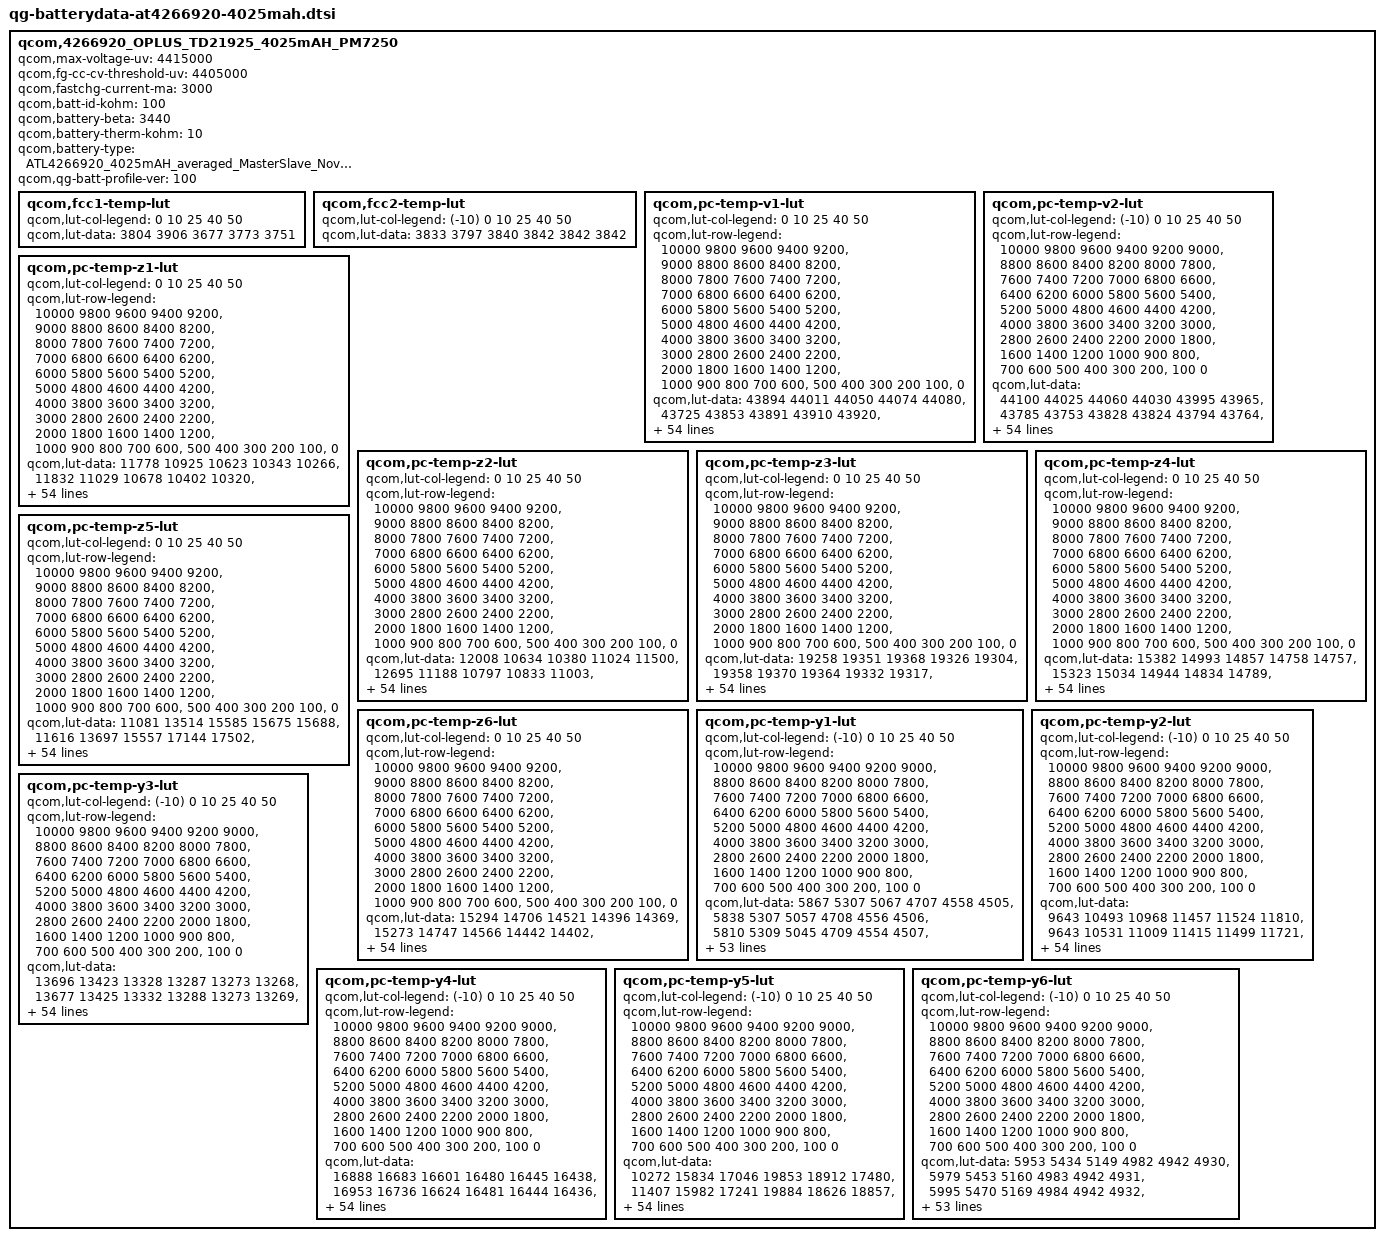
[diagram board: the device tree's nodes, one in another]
qcom,4266920_OPLUS_TD21925_4025mAH_PM7250 {
    /* 4266920_OPLUS_TD21925_4025mAH_PM7250_averaged_MasterSlave_Nov29th2019 */
    qcom,max-voltage-uv = <4415000>;
    qcom,fg-cc-cv-threshold-uv = <4405000>;
    qcom,fastchg-current-ma = <3000>;
    qcom,batt-id-kohm = <100>;
    qcom,battery-beta = <3440>;
    qcom,battery-therm-kohm = <10>;
    qcom,battery-type = "ATL4266920_4025mAH_averaged_MasterSlave_Nov29th2019";
    qcom,qg-batt-profile-ver = <100>;


	qcom,fcc1-temp-lut {
		qcom,lut-col-legend = <0 10 25 40 50>;
		qcom,lut-data = <3804 3906 3677 3773 3751>;
	};

	qcom,fcc2-temp-lut {
		qcom,lut-col-legend = <(-10) 0 10 25 40 50>;
		qcom,lut-data = <3833 3797 3840 3842 3842 3842>;
	};

	qcom,pc-temp-v1-lut {
		qcom,lut-col-legend = <0 10 25 40 50>;
		qcom,lut-row-legend = <10000 9800 9600 9400 9200>,
			<9000 8800 8600 8400 8200>,
			<8000 7800 7600 7400 7200>,
			<7000 6800 6600 6400 6200>,
			<6000 5800 5600 5400 5200>,
			<5000 4800 4600 4400 4200>,
			<4000 3800 3600 3400 3200>,
			<3000 2800 2600 2400 2200>,
			<2000 1800 1600 1400 1200>,
			<1000 900 800 700 600>,
			<500 400 300 200 100>,
			<0>;
		qcom,lut-data = <43894 44011 44050 44074 44080>,
			<43725 43853 43891 43910 43920>,
			<43525 43681 43703 43730 43743>,
			<43298 43490 43505 43539 43554>,
			<43066 43276 43296 43337 43354>,
			<42830 43046 43076 43121 43140>,
			<42595 42811 42850 42899 42917>,
			<42367 42574 42617 42672 42690>,
			<42143 42341 42384 42440 42457>,
			<41922 42111 42152 42208 42224>,
			<41705 41883 41921 41975 41991>,
			<41492 41660 41694 41745 41759>,
			<41283 41441 41472 41520 41535>,
			<41082 41229 41255 41299 41315>,
			<40886 41025 41045 41085 41100>,
			<40689 40827 40841 40879 40890>,
			<40488 40635 40644 40680 40686>,
			<40290 40448 40461 40492 40493>,
			<40104 40249 40281 40313 40314>,
			<39931 39996 40064 40115 40122>,
			<39748 39701 39784 39859 39880>,
			<39513 39457 39520 39593 39616>,
			<39249 39296 39341 39388 39402>,
			<39059 39170 39197 39223 39234>,
			<38950 39052 39066 39078 39087>,
			<38866 38940 38940 38946 38952>,
			<38783 38835 38823 38827 38830>,
			<38704 38733 38715 38717 38716>,
			<38629 38637 38614 38616 38609>,
			<38557 38550 38521 38521 38509>,
			<38489 38476 38437 38433 38417>,
			<38426 38407 38361 38350 38332>,
			<38371 38347 38292 38273 38253>,
			<38320 38291 38231 38203 38181>,
			<38274 38240 38174 38136 38111>,
			<38236 38197 38118 38064 38032>,
			<38195 38157 38065 37990 37943>,
			<38132 38102 38001 37909 37849>,
			<38036 38011 37912 37819 37751>,
			<37924 37894 37802 37718 37646>,
			<37803 37769 37683 37604 37528>,
			<37664 37628 37549 37469 37392>,
			<37503 37469 37399 37325 37246>,
			<37345 37296 37230 37167 37087>,
			<37248 37178 37115 37058 36992>,
			<37170 37119 37058 37006 36946>,
			<37145 37093 37040 36989 36931>,
			<37121 37071 37022 36973 36915>,
			<37069 37028 36974 36931 36854>,
			<36894 36849 36792 36732 36587>,
			<36507 36451 36400 36344 36189>,
			<36007 35950 35911 35860 35692>,
			<35368 35309 35285 35235 35052>,
			<34487 34417 34431 34384 34171>,
			<33063 32979 33080 33048 32769>,
			<30000 30000 30000 30000 30000>;
	};

	qcom,pc-temp-v2-lut {
		qcom,lut-col-legend = <(-10) 0 10 25 40 50>;
		qcom,lut-row-legend = <10000 9800 9600 9400 9200 9000>,
			<8800 8600 8400 8200 8000 7800>,
			<7600 7400 7200 7000 6800 6600>,
			<6400 6200 6000 5800 5600 5400>,
			<5200 5000 4800 4600 4400 4200>,
			<4000 3800 3600 3400 3200 3000>,
			<2800 2600 2400 2200 2000 1800>,
			<1600 1400 1200 1000 900 800>,
			<700 600 500 400 300 200>,
			<100 0>;
		qcom,lut-data = <44100 44025 44060 44030 43995 43965>,
			<43785 43753 43828 43824 43794 43764>,
			<43492 43491 43599 43615 43589 43559>,
			<43225 43241 43373 43404 43380 43351>,
			<42986 43007 43152 43189 43168 43138>,
			<42753 42776 42929 42970 42951 42921>,
			<42504 42537 42697 42743 42725 42696>,
			<42247 42293 42459 42509 42494 42465>,
			<41988 42056 42223 42276 42263 42235>,
			<41705 41833 41986 42044 42033 42004>,
			<41437 41615 41753 41813 41804 41776>,
			<41262 41387 41526 41586 41580 41551>,
			<41150 41143 41305 41363 41358 41330>,
			<41024 40915 41090 41146 41142 41114>,
			<40804 40739 40883 40935 40930 40905>,
			<40485 40592 40683 40730 40724 40702>,
			<40174 40412 40479 40531 40525 40505>,
			<39879 40145 40272 40344 40341 40323>,
			<39597 39840 40056 40150 40150 40134>,
			<39345 39573 39811 39913 39918 39903>,
			<39106 39328 39541 39637 39646 39631>,
			<38895 39105 39302 39390 39405 39392>,
			<38706 38910 39108 39195 39216 39207>,
			<38542 38735 38939 39025 39053 39047>,
			<38424 38569 38787 38877 38910 38906>,
			<38338 38394 38653 38749 38783 38779>,
			<38267 38240 38530 38631 38666 38663>,
			<38203 38149 38414 38521 38557 38556>,
			<38147 38089 38305 38418 38455 38456>,
			<38092 38041 38199 38322 38360 38361>,
			<38039 37996 38092 38232 38274 38274>,
			<37988 37956 37993 38147 38192 38190>,
			<37934 37915 37923 38070 38112 38107>,
			<37877 37871 37870 37999 38033 38023>,
			<37818 37825 37823 37924 37945 37928>,
			<37753 37774 37780 37836 37837 37809>,
			<37683 37716 37736 37740 37718 37677>,
			<37606 37650 37679 37645 37610 37561>,
			<37520 37565 37600 37554 37514 37464>,
			<37423 37461 37504 37459 37416 37366>,
			<37311 37343 37388 37352 37304 37252>,
			<37181 37198 37245 37232 37177 37122>,
			<37062 37050 37100 37109 37055 36998>,
			<36965 36923 36950 36978 36935 36884>,
			<36884 36816 36835 36891 36860 36813>,
			<36814 36747 36777 36860 36833 36788>,
			<36774 36725 36748 36842 36819 36773>,
			<36716 36693 36706 36810 36788 36735>,
			<36608 36615 36609 36723 36687 36603>,
			<36400 36429 36390 36522 36444 36303>,
			<36033 36062 35963 36095 35999 35849>,
			<35500 35519 35401 35563 35465 35295>,
			<34766 34822 34683 34889 34766 34567>,
			<33702 33829 33674 33961 33824 33553>,
			<31807 32174 32032 32452 32402 31793>,
			<27093 27571 27094 29575 28936 27567>;
	};

	qcom,pc-temp-z1-lut {
		qcom,lut-col-legend = <0 10 25 40 50>;
		qcom,lut-row-legend = <10000 9800 9600 9400 9200>,
			<9000 8800 8600 8400 8200>,
			<8000 7800 7600 7400 7200>,
			<7000 6800 6600 6400 6200>,
			<6000 5800 5600 5400 5200>,
			<5000 4800 4600 4400 4200>,
			<4000 3800 3600 3400 3200>,
			<3000 2800 2600 2400 2200>,
			<2000 1800 1600 1400 1200>,
			<1000 900 800 700 600>,
			<500 400 300 200 100>,
			<0>;
		qcom,lut-data = <11778 10925 10623 10343 10266>,
			<11832 11029 10678 10402 10320>,
			<11841 11179 10689 10412 10334>,
			<11839 11265 10691 10415 10339>,
			<11841 11255 10686 10414 10341>,
			<11845 11239 10679 10413 10342>,
			<11843 11224 10673 10412 10342>,
			<11829 11208 10667 10411 10342>,
			<11799 11191 10663 10410 10341>,
			<11769 11172 10660 10409 10341>,
			<11755 11162 10658 10408 10341>,
			<11752 11163 10657 10407 10340>,
			<11754 11173 10659 10408 10340>,
			<11751 11182 10660 10408 10341>,
			<11749 11177 10661 10408 10342>,
			<11747 11167 10663 10408 10343>,
			<11744 11165 10663 10409 10343>,
			<11740 11171 10663 10409 10344>,
			<11735 11176 10663 10410 10345>,
			<11726 11171 10663 10411 10345>,
			<11722 11163 10664 10411 10346>,
			<11727 11162 10666 10411 10347>,
			<11730 11169 10667 10412 10348>,
			<11733 11178 10669 10414 10349>,
			<11743 11180 10671 10417 10351>,
			<11756 11179 10678 10419 10353>,
			<11762 11177 10687 10421 10355>,
			<11761 11175 10692 10423 10357>,
			<11759 11176 10694 10426 10359>,
			<11763 11179 10696 10428 10361>,
			<11770 11192 10697 10430 10363>,
			<11772 11206 10699 10433 10365>,
			<11760 11207 10701 10436 10368>,
			<11744 11199 10709 10439 10371>,
			<11740 11195 10718 10442 10373>,
			<11747 11199 10724 10445 10376>,
			<11756 11207 10731 10448 10378>,
			<11764 11216 10734 10451 10380>,
			<11777 11236 10737 10454 10382>,
			<11793 11259 10739 10456 10383>,
			<11821 11264 10742 10458 10384>,
			<11852 11264 10749 10460 10386>,
			<11846 11258 10753 10461 10387>,
			<11833 11246 10756 10461 10388>,
			<11870 11253 10766 10462 10389>,
			<11826 11250 10766 10465 10389>,
			<11825 11246 10764 10466 10390>,
			<11805 11251 10772 10466 10390>,
			<11814 11270 10779 10468 10392>,
			<11817 11289 10788 10472 10394>,
			<11835 11274 10794 10474 10397>,
			<11874 11291 10797 10480 10400>,
			<11870 11295 10803 10484 10404>,
			<11879 11315 10816 10492 10411>,
			<11879 11315 10816 10492 10411>,
			<11879 11315 10816 10492 10411>;
	};

	qcom,pc-temp-z2-lut {
		qcom,lut-col-legend = <0 10 25 40 50>;
		qcom,lut-row-legend = <10000 9800 9600 9400 9200>,
			<9000 8800 8600 8400 8200>,
			<8000 7800 7600 7400 7200>,
			<7000 6800 6600 6400 6200>,
			<6000 5800 5600 5400 5200>,
			<5000 4800 4600 4400 4200>,
			<4000 3800 3600 3400 3200>,
			<3000 2800 2600 2400 2200>,
			<2000 1800 1600 1400 1200>,
			<1000 900 800 700 600>,
			<500 400 300 200 100>,
			<0>;
		qcom,lut-data = <12008 10634 10380 11024 11500>,
			<12695 11188 10797 10833 11003>,
			<12009 11320 10764 10873 10873>,
			<11090 11152 10728 10901 10813>,
			<10556 10927 10673 10878 10793>,
			<10360 10728 10609 10813 10786>,
			<10245 10507 10587 10761 10782>,
			<10217 10371 10590 10713 10762>,
			<10202 10358 10598 10665 10735>,
			<10194 10366 10607 10650 10727>,
			<10193 10383 10617 10651 10738>,
			<10196 10396 10621 10656 10756>,
			<10203 10404 10619 10665 10775>,
			<10223 10411 10616 10680 10796>,
			<10251 10419 10618 10693 10809>,
			<10262 10427 10631 10710 10815>,
			<10264 10434 10642 10728 10820>,
			<10266 10441 10643 10744 10836>,
			<10270 10446 10643 10761 10875>,
			<10277 10443 10637 10779 10917>,
			<10282 10424 10611 10805 10958>,
			<10276 10406 10590 10833 10995>,
			<10264 10400 10626 10854 10997>,
			<10257 10402 10722 10882 10912>,
			<10261 10412 10766 10891 10797>,
			<10267 10431 10717 10839 10713>,
			<10273 10444 10644 10750 10635>,
			<10277 10440 10622 10692 10610>,
			<10281 10429 10615 10652 10632>,
			<10287 10423 10614 10628 10672>,
			<10294 10430 10626 10634 10714>,
			<10302 10444 10651 10661 10771>,
			<10310 10457 10673 10691 10829>,
			<10318 10470 10691 10723 10886>,
			<10325 10482 10707 10765 10940>,
			<10330 10489 10719 10831 10984>,
			<10335 10493 10728 10947 11031>,
			<10347 10501 10742 11027 11077>,
			<10370 10521 10784 11036 11132>,
			<10386 10541 10834 11036 11191>,
			<10382 10541 10841 11043 11197>,
			<10374 10530 10819 11075 11078>,
			<10386 10529 10812 11081 11009>,
			<10414 10548 10819 10970 11046>,
			<10283 10659 10857 10988 11085>,
			<10258 10670 10822 10970 11038>,
			<11590 10663 10805 10984 11052>,
			<10569 10695 10764 10976 11136>,
			<11295 10808 10781 11011 11182>,
			<11016 10748 10877 10902 10841>,
			<9937 10752 10852 10768 10776>,
			<9848 10743 10817 10744 10720>,
			<9707 10779 10733 10650 10658>,
			<9596 10547 10651 10578 10567>,
			<9596 10547 10651 10578 10567>,
			<9596 10547 10651 10578 10567>;
	};

	qcom,pc-temp-z3-lut {
		qcom,lut-col-legend = <0 10 25 40 50>;
		qcom,lut-row-legend = <10000 9800 9600 9400 9200>,
			<9000 8800 8600 8400 8200>,
			<8000 7800 7600 7400 7200>,
			<7000 6800 6600 6400 6200>,
			<6000 5800 5600 5400 5200>,
			<5000 4800 4600 4400 4200>,
			<4000 3800 3600 3400 3200>,
			<3000 2800 2600 2400 2200>,
			<2000 1800 1600 1400 1200>,
			<1000 900 800 700 600>,
			<500 400 300 200 100>,
			<0>;
		qcom,lut-data = <19258 19351 19368 19326 19304>,
			<19358 19370 19364 19332 19317>,
			<19451 19421 19390 19348 19327>,
			<19546 19478 19411 19364 19336>,
			<19612 19511 19420 19368 19341>,
			<19646 19525 19426 19371 19343>,
			<19667 19532 19426 19371 19344>,
			<19669 19534 19421 19364 19341>,
			<19668 19533 19414 19353 19338>,
			<19666 19528 19410 19349 19336>,
			<19663 19522 19406 19348 19335>,
			<19659 19517 19403 19347 19334>,
			<19654 19514 19399 19346 19331>,
			<19645 19511 19396 19344 19325>,
			<19636 19508 19394 19342 19322>,
			<19634 19505 19394 19338 19321>,
			<19637 19502 19393 19333 19320>,
			<19641 19499 19391 19330 19319>,
			<19641 19497 19389 19329 19316>,
			<19637 19504 19389 19327 19315>,
			<19634 19520 19390 19327 19316>,
			<19640 19529 19392 19328 19321>,
			<19653 19518 19392 19334 19327>,
			<19658 19500 19392 19359 19342>,
			<19654 19495 19394 19378 19354>,
			<19646 19505 19408 19379 19353>,
			<19642 19517 19424 19378 19350>,
			<19639 19522 19426 19376 19347>,
			<19637 19525 19423 19367 19344>,
			<19635 19526 19418 19357 19341>,
			<19634 19522 19412 19350 19336>,
			<19633 19516 19406 19345 19330>,
			<19631 19512 19401 19341 19325>,
			<19629 19511 19398 19338 19321>,
			<19626 19509 19396 19336 19317>,
			<19623 19507 19395 19337 19316>,
			<19618 19505 19395 19339 19317>,
			<19613 19502 19394 19341 19319>,
			<19607 19496 19392 19340 19323>,
			<19599 19490 19388 19338 19328>,
			<19594 19485 19385 19338 19329>,
			<19587 19483 19383 19340 19327>,
			<19579 19479 19380 19341 19326>,
			<19557 19471 19376 19335 19331>,
			<19314 19443 19364 19326 19319>,
			<19299 19423 19360 19320 19312>,
			<19272 19423 19357 19320 19309>,
			<19263 19413 19355 19316 19301>,
			<19262 19380 19352 19316 19302>,
			<19263 19395 19346 19333 19326>,
			<19266 19377 19344 19339 19328>,
			<19268 19364 19347 19341 19329>,
			<19273 19323 19353 19343 19330>,
			<19279 19336 19353 19345 19333>,
			<19279 19336 19353 19345 19333>,
			<19279 19336 19353 19345 19333>;
	};

	qcom,pc-temp-z4-lut {
		qcom,lut-col-legend = <0 10 25 40 50>;
		qcom,lut-row-legend = <10000 9800 9600 9400 9200>,
			<9000 8800 8600 8400 8200>,
			<8000 7800 7600 7400 7200>,
			<7000 6800 6600 6400 6200>,
			<6000 5800 5600 5400 5200>,
			<5000 4800 4600 4400 4200>,
			<4000 3800 3600 3400 3200>,
			<3000 2800 2600 2400 2200>,
			<2000 1800 1600 1400 1200>,
			<1000 900 800 700 600>,
			<500 400 300 200 100>,
			<0>;
		qcom,lut-data = <15382 14993 14857 14758 14757>,
			<15323 15034 14944 14834 14789>,
			<15256 15058 14916 14814 14780>,
			<15180 15043 14881 14782 14756>,
			<15106 14986 14843 14755 14733>,
			<15035 14920 14803 14728 14710>,
			<14971 14871 14774 14712 14694>,
			<14921 14834 14750 14707 14689>,
			<14882 14800 14734 14704 14685>,
			<14850 14772 14725 14699 14680>,
			<14822 14753 14718 14692 14674>,
			<14797 14743 14712 14684 14667>,
			<14779 14738 14707 14676 14663>,
			<14767 14735 14702 14669 14660>,
			<14759 14732 14697 14664 14656>,
			<14757 14730 14690 14660 14650>,
			<14759 14729 14687 14658 14644>,
			<14762 14732 14687 14656 14641>,
			<14763 14738 14687 14654 14639>,
			<14762 14769 14697 14655 14638>,
			<14761 14833 14767 14703 14668>,
			<14792 14873 14833 14770 14724>,
			<14860 14878 14835 14778 14739>,
			<14893 14878 14826 14749 14720>,
			<14881 14870 14812 14720 14698>,
			<14861 14840 14782 14705 14689>,
			<14842 14805 14748 14694 14682>,
			<14822 14784 14732 14687 14675>,
			<14805 14770 14722 14683 14669>,
			<14793 14764 14717 14680 14663>,
			<14783 14763 14715 14676 14659>,
			<14776 14762 14713 14672 14656>,
			<14773 14763 14713 14670 14654>,
			<14770 14765 14715 14670 14655>,
			<14766 14767 14718 14671 14656>,
			<14761 14765 14721 14673 14660>,
			<14755 14760 14725 14684 14674>,
			<14753 14758 14728 14693 14684>,
			<14752 14756 14729 14694 14682>,
			<14751 14755 14730 14694 14675>,
			<14744 14750 14728 14693 14670>,
			<14733 14734 14714 14684 14669>,
			<14722 14722 14706 14679 14667>,
			<14717 14712 14702 14683 14664>,
			<14883 14677 14676 14673 14657>,
			<14892 14666 14653 14654 14641>,
			<14911 14658 14642 14638 14630>,
			<14917 14665 14636 14630 14626>,
			<14913 14697 14638 14628 14626>,
			<14916 14686 14657 14631 14626>,
			<14927 14714 14664 14629 14626>,
			<14933 14731 14661 14627 14627>,
			<14942 14782 14654 14627 14627>,
			<14954 14776 14658 14626 14626>,
			<14954 14776 14658 14626 14626>,
			<14954 14776 14658 14626 14626>;
	};

	qcom,pc-temp-z5-lut {
		qcom,lut-col-legend = <0 10 25 40 50>;
		qcom,lut-row-legend = <10000 9800 9600 9400 9200>,
			<9000 8800 8600 8400 8200>,
			<8000 7800 7600 7400 7200>,
			<7000 6800 6600 6400 6200>,
			<6000 5800 5600 5400 5200>,
			<5000 4800 4600 4400 4200>,
			<4000 3800 3600 3400 3200>,
			<3000 2800 2600 2400 2200>,
			<2000 1800 1600 1400 1200>,
			<1000 900 800 700 600>,
			<500 400 300 200 100>,
			<0>;
		qcom,lut-data = <11081 13514 15585 15675 15688>,
			<11616 13697 15557 17144 17502>,
			<12557 14420 16794 18294 18274>,
			<14170 15541 17824 19255 18813>,
			<15861 16779 18492 20123 19668>,
			<17512 18073 19077 20958 21003>,
			<19011 19535 19718 21314 21840>,
			<19992 20981 20407 20664 21755>,
			<20721 22321 20884 19675 21445>,
			<21455 23699 21172 19499 21598>,
			<22457 25075 21484 19959 22595>,
			<23727 26139 21831 20606 23534>,
			<24831 26805 22164 21430 23334>,
			<25478 27232 22557 22437 22392>,
			<26025 27646 23327 22868 21933>,
			<26993 28038 24752 22532 23115>,
			<29248 28198 25678 22079 24958>,
			<31302 27966 25819 22189 25830>,
			<31498 27638 25887 22599 26323>,
			<31083 31321 25810 22761 26545>,
			<30870 39527 24838 20771 23942>,
			<34160 43306 23326 18000 19127>,
			<40770 36624 21380 17594 17778>,
			<43475 26778 18950 18667 18748>,
			<39402 23642 18026 20109 19743>,
			<33541 24240 19829 21874 20327>,
			<31441 25470 22819 23799 21258>,
			<30877 28224 25239 24352 22369>,
			<30723 32343 27639 24131 23863>,
			<31391 35277 29753 23909 25381>,
			<33404 36835 31288 24197 26375>,
			<35402 38020 32561 25278 27151>,
			<37001 39240 33649 26497 27593>,
			<38383 40579 34766 28274 27843>,
			<38762 41350 35492 30053 28028>,
			<38756 41312 35444 30522 27796>,
			<38749 40956 35024 30649 26096>,
			<38873 40377 34392 30700 24753>,
			<39348 38814 32291 29077 25735>,
			<39678 36961 29468 25935 27940>,
			<38785 36132 28315 25060 28652>,
			<36694 35666 27961 26446 27574>,
			<35487 34999 27089 26863 26785>,
			<33469 34023 24974 22793 27528>,
			<12763 34096 26462 21651 23308>,
			<12091 27542 29733 22625 24002>,
			<11600 28188 29990 26876 27651>,
			<11427 27290 30142 29844 27875>,
			<11438 20199 28348 30287 26773>,
			<11477 20325 20638 30548 37240>,
			<11483 17160 18585 32521 37130>,
			<11432 15280 18606 33284 35995>,
			<11389 12790 19696 33340 35070>,
			<11326 13049 18992 33494 35261>,
			<11326 13049 18992 33494 35261>,
			<11326 13049 18992 33494 35261>;
	};

	qcom,pc-temp-z6-lut {
		qcom,lut-col-legend = <0 10 25 40 50>;
		qcom,lut-row-legend = <10000 9800 9600 9400 9200>,
			<9000 8800 8600 8400 8200>,
			<8000 7800 7600 7400 7200>,
			<7000 6800 6600 6400 6200>,
			<6000 5800 5600 5400 5200>,
			<5000 4800 4600 4400 4200>,
			<4000 3800 3600 3400 3200>,
			<3000 2800 2600 2400 2200>,
			<2000 1800 1600 1400 1200>,
			<1000 900 800 700 600>,
			<500 400 300 200 100>,
			<0>;
		qcom,lut-data = <15294 14706 14521 14396 14369>,
			<15273 14747 14566 14442 14402>,
			<15253 14823 14565 14441 14403>,
			<15235 14866 14562 14438 14399>,
			<15213 14845 14551 14433 14395>,
			<15181 14812 14534 14423 14387>,
			<15138 14781 14519 14414 14380>,
			<15098 14755 14505 14406 14375>,
			<15063 14730 14493 14400 14372>,
			<15032 14707 14486 14396 14369>,
			<15006 14692 14481 14391 14365>,
			<14982 14683 14476 14387 14362>,
			<14963 14679 14472 14383 14358>,
			<14949 14675 14468 14380 14354>,
			<14939 14670 14465 14376 14351>,
			<14937 14667 14462 14372 14347>,
			<14938 14666 14460 14368 14344>,
			<14939 14666 14459 14366 14342>,
			<14939 14666 14458 14365 14340>,
			<14936 14682 14462 14365 14339>,
			<14933 14718 14494 14386 14354>,
			<14950 14741 14524 14415 14381>,
			<14988 14740 14525 14421 14390>,
			<15007 14733 14522 14421 14390>,
			<15002 14726 14519 14421 14388>,
			<14994 14720 14514 14418 14385>,
			<14986 14714 14508 14412 14380>,
			<14978 14710 14503 14407 14376>,
			<14971 14707 14498 14401 14372>,
			<14968 14705 14494 14395 14368>,
			<14965 14704 14490 14390 14363>,
			<14964 14702 14487 14385 14359>,
			<14964 14703 14486 14383 14356>,
			<14965 14705 14486 14382 14354>,
			<14965 14707 14487 14381 14353>,
			<14966 14708 14489 14382 14353>,
			<14968 14709 14493 14389 14361>,
			<14970 14709 14495 14394 14366>,
			<14974 14710 14495 14394 14367>,
			<14977 14710 14495 14394 14367>,
			<14977 14709 14494 14393 14367>,
			<14977 14705 14489 14391 14364>,
			<14976 14703 14485 14389 14363>,
			<14973 14701 14482 14388 14365>,
			<14934 14681 14468 14380 14357>,
			<14930 14668 14457 14368 14345>,
			<14928 14666 14451 14362 14339>,
			<14927 14666 14448 14356 14333>,
			<14929 14667 14449 14356 14334>,
			<14940 14674 14456 14366 14347>,
			<14954 14680 14460 14370 14349>,
			<14965 14686 14462 14371 14351>,
			<14980 14695 14465 14373 14353>,
			<15003 14709 14470 14376 14355>,
			<15003 14709 14470 14376 14355>,
			<15003 14709 14470 14376 14355>;
	};

	qcom,pc-temp-y1-lut {
		qcom,lut-col-legend = <(-10) 0 10 25 40 50>;
		qcom,lut-row-legend = <10000 9800 9600 9400 9200 9000>,
			<8800 8600 8400 8200 8000 7800>,
			<7600 7400 7200 7000 6800 6600>,
			<6400 6200 6000 5800 5600 5400>,
			<5200 5000 4800 4600 4400 4200>,
			<4000 3800 3600 3400 3200 3000>,
			<2800 2600 2400 2200 2000 1800>,
			<1600 1400 1200 1000 900 800>,
			<700 600 500 400 300 200>,
			<100 0>;
		qcom,lut-data = <5867 5307 5067 4707 4558 4505>,
			<5838 5307 5057 4708 4556 4506>,
			<5810 5309 5045 4709 4554 4507>,
			<5785 5312 5032 4709 4552 4507>,
			<5768 5315 5022 4709 4550 4508>,
			<5759 5318 5016 4709 4548 4508>,
			<5766 5322 5015 4708 4548 4508>,
			<5788 5329 5016 4705 4548 4507>,
			<5798 5332 5017 4704 4547 4506>,
			<5792 5329 5020 4704 4547 4506>,
			<5783 5324 5023 4704 4547 4506>,
			<5787 5324 5023 4704 4547 4506>,
			<5807 5335 5022 4704 4546 4507>,
			<5826 5346 5019 4704 4545 4507>,
			<5834 5344 5013 4703 4545 4507>,
			<5839 5336 5006 4702 4545 4508>,
			<5839 5332 5004 4701 4546 4508>,
			<5820 5347 5008 4701 4546 4508>,
			<5798 5367 5012 4701 4546 4508>,
			<5793 5368 5017 4702 4547 4508>,
			<5792 5352 5023 4705 4548 4508>,
			<5792 5339 5026 4708 4549 4508>,
			<5793 5344 5024 4712 4549 4510>,
			<5795 5360 5020 4715 4550 4511>,
			<5795 5369 5019 4715 4551 4512>,
			<5794 5377 5018 4715 4551 4512>,
			<5795 5384 5017 4715 4552 4512>,
			<5802 5383 5022 4716 4553 4513>,
			<5815 5371 5030 4718 4554 4514>,
			<5823 5360 5033 4721 4555 4515>,
			<5813 5360 5031 4723 4556 4516>,
			<5793 5361 5030 4726 4558 4517>,
			<5785 5361 5032 4729 4559 4518>,
			<5782 5355 5033 4733 4561 4520>,
			<5779 5347 5033 4737 4562 4520>,
			<5779 5344 5034 4739 4563 4520>,
			<5784 5346 5037 4740 4564 4520>,
			<5789 5351 5039 4742 4564 4520>,
			<5791 5365 5041 4744 4565 4522>,
			<5793 5382 5043 4747 4567 4523>,
			<5796 5387 5046 4750 4568 4524>,
			<5799 5384 5054 4752 4569 4525>,
			<5797 5379 5060 4756 4570 4526>,
			<5789 5373 5060 4760 4571 4526>,
			<5798 5366 5060 4766 4572 4527>,
			<5842 5367 5071 4776 4574 4528>,
			<5851 5366 5077 4782 4575 4529>,
			<5847 5363 5076 4783 4575 4529>,
			<5832 5365 5069 4782 4575 4529>,
			<5847 5379 5077 4780 4576 4529>,
			<5917 5423 5083 4778 4577 4531>,
			<6033 5434 5100 4792 4579 4533>,
			<6083 5478 5114 4795 4582 4536>,
			<6227 5509 5160 4803 4587 4540>,
			<6227 5509 5160 4803 4587 4540>,
			<6227 5509 5160 4803 4587 4540>;
	};

	qcom,pc-temp-y2-lut {
		qcom,lut-col-legend = <(-10) 0 10 25 40 50>;
		qcom,lut-row-legend = <10000 9800 9600 9400 9200 9000>,
			<8800 8600 8400 8200 8000 7800>,
			<7600 7400 7200 7000 6800 6600>,
			<6400 6200 6000 5800 5600 5400>,
			<5200 5000 4800 4600 4400 4200>,
			<4000 3800 3600 3400 3200 3000>,
			<2800 2600 2400 2200 2000 1800>,
			<1600 1400 1200 1000 900 800>,
			<700 600 500 400 300 200>,
			<100 0>;
		qcom,lut-data = <9643 10493 10968 11457 11524 11810>,
			<9643 10531 11009 11415 11499 11721>,
			<9805 10577 11035 11374 11471 11625>,
			<10008 10624 11050 11334 11442 11531>,
			<10183 10665 11056 11300 11413 11449>,
			<10296 10693 11056 11272 11385 11390>,
			<10338 10707 11046 11251 11359 11353>,
			<10363 10716 11021 11235 11332 11325>,
			<10379 10720 11000 11221 11305 11312>,
			<10335 10718 10984 11208 11273 11307>,
			<10248 10716 10973 11198 11246 11303>,
			<10207 10717 10974 11194 11247 11304>,
			<10146 10735 10989 11192 11274 11311>,
			<10106 10767 11014 11192 11303 11316>,
			<10145 10844 11064 11203 11319 11320>,
			<10211 10984 11146 11233 11332 11336>,
			<10201 11049 11221 11279 11355 11358>,
			<9942 11042 11303 11400 11424 11399>,
			<9699 11026 11361 11507 11500 11453>,
			<9679 11009 11344 11511 11544 11530>,
			<9677 10988 11272 11482 11582 11647>,
			<9675 10959 11233 11460 11591 11704>,
			<9673 10907 11234 11452 11606 11693>,
			<9671 10822 11234 11449 11635 11673>,
			<9670 10728 11235 11453 11649 11689>,
			<9669 10520 11233 11464 11655 11747>,
			<9669 10314 11228 11477 11662 11798>,
			<9668 10240 11213 11501 11687 11822>,
			<9667 10036 11189 11542 11739 11843>,
			<9667 9837 11172 11570 11780 11872>,
			<9666 9773 11158 11583 11818 11926>,
			<9665 9736 11146 11593 11859 11989>,
			<9664 9713 11136 11609 11889 12042>,
			<9664 9697 11123 11630 11926 12101>,
			<9663 9685 11105 11642 11945 12118>,
			<9663 9678 11067 11615 11860 12055>,
			<9663 9673 11006 11556 11718 11968>,
			<9662 9669 10933 11521 11680 11924>,
			<9662 9666 10842 11506 11713 11885>,
			<9661 9664 10730 11496 11747 11846>,
			<9661 9662 10587 11488 11743 11804>,
			<9661 9661 10372 11464 11720 11758>,
			<9661 9660 10152 11420 11691 11749>,
			<9660 9659 9928 11306 11652 11738>,
			<9659 9659 9772 11218 11584 11686>,
			<9658 9658 9701 11182 11433 11483>,
			<9657 9658 9686 11162 11404 11427>,
			<9656 9657 9678 11120 11430 11435>,
			<9654 9656 9674 11098 11460 11432>,
			<9653 9656 9673 11124 11440 11395>,
			<9650 9655 9667 11108 11373 11400>,
			<9649 9653 9661 11033 11289 11260>,
			<9648 9651 9658 11001 11211 11175>,
			<9648 9649 9655 10953 11097 11079>,
			<9648 9649 9655 10953 11097 11079>,
			<9648 9649 9655 10953 11097 11079>;
	};

	qcom,pc-temp-y3-lut {
		qcom,lut-col-legend = <(-10) 0 10 25 40 50>;
		qcom,lut-row-legend = <10000 9800 9600 9400 9200 9000>,
			<8800 8600 8400 8200 8000 7800>,
			<7600 7400 7200 7000 6800 6600>,
			<6400 6200 6000 5800 5600 5400>,
			<5200 5000 4800 4600 4400 4200>,
			<4000 3800 3600 3400 3200 3000>,
			<2800 2600 2400 2200 2000 1800>,
			<1600 1400 1200 1000 900 800>,
			<700 600 500 400 300 200>,
			<100 0>;
		qcom,lut-data = <13696 13423 13328 13287 13273 13268>,
			<13677 13425 13332 13288 13273 13269>,
			<13652 13426 13335 13289 13274 13270>,
			<13626 13428 13339 13290 13274 13272>,
			<13603 13430 13341 13292 13275 13273>,
			<13585 13431 13344 13292 13276 13274>,
			<13574 13433 13345 13293 13276 13274>,
			<13565 13434 13347 13294 13277 13275>,
			<13557 13436 13348 13295 13278 13275>,
			<13550 13445 13349 13296 13280 13276>,
			<13544 13455 13351 13297 13281 13276>,
			<13538 13453 13353 13297 13283 13277>,
			<13524 13415 13356 13297 13285 13277>,
			<13515 13382 13358 13298 13286 13278>,
			<13516 13387 13352 13299 13286 13279>,
			<13519 13407 13338 13301 13286 13282>,
			<13521 13417 13334 13302 13286 13283>,
			<13518 13406 13336 13302 13287 13283>,
			<13511 13388 13339 13301 13288 13282>,
			<13503 13377 13337 13300 13287 13280>,
			<13494 13368 13330 13295 13282 13276>,
			<13486 13362 13324 13291 13278 13273>,
			<13478 13356 13321 13289 13277 13272>,
			<13471 13352 13319 13288 13276 13271>,
			<13471 13347 13318 13288 13276 13271>,
			<13482 13341 13317 13288 13276 13271>,
			<13498 13335 13316 13288 13275 13270>,
			<13517 13335 13315 13287 13275 13271>,
			<13541 13338 13313 13287 13274 13272>,
			<13565 13342 13312 13287 13274 13273>,
			<13592 13353 13310 13287 13274 13272>,
			<13622 13370 13309 13287 13275 13271>,
			<13656 13389 13309 13287 13275 13271>,
			<13692 13406 13309 13287 13275 13272>,
			<13729 13426 13310 13287 13276 13272>,
			<13767 13453 13313 13286 13275 13272>,
			<13805 13488 13316 13285 13273 13271>,
			<13845 13529 13319 13284 13273 13271>,
			<13885 13579 13321 13283 13273 13271>,
			<13923 13638 13324 13282 13273 13271>,
			<13955 13697 13329 13282 13273 13271>,
			<13983 13759 13336 13283 13274 13272>,
			<14016 13822 13345 13284 13274 13272>,
			<14063 13879 13361 13286 13274 13271>,
			<14131 13933 13385 13288 13273 13271>,
			<14247 14003 13429 13296 13278 13276>,
			<14335 14046 13460 13301 13282 13278>,
			<14466 14099 13502 13305 13283 13279>,
			<14655 14173 13537 13306 13283 13278>,
			<14958 14262 13537 13303 13281 13276>,
			<15940 14365 13555 13298 13278 13275>,
			<18338 14653 13685 13301 13281 13278>,
			<24080 15494 13906 13307 13282 13279>,
			<39680 17820 14267 13315 13285 13281>,
			<39680 17820 14267 13315 13285 13281>,
			<39680 17820 14267 13315 13285 13281>;
	};

	qcom,pc-temp-y4-lut {
		qcom,lut-col-legend = <(-10) 0 10 25 40 50>;
		qcom,lut-row-legend = <10000 9800 9600 9400 9200 9000>,
			<8800 8600 8400 8200 8000 7800>,
			<7600 7400 7200 7000 6800 6600>,
			<6400 6200 6000 5800 5600 5400>,
			<5200 5000 4800 4600 4400 4200>,
			<4000 3800 3600 3400 3200 3000>,
			<2800 2600 2400 2200 2000 1800>,
			<1600 1400 1200 1000 900 800>,
			<700 600 500 400 300 200>,
			<100 0>;
		qcom,lut-data = <16888 16683 16601 16480 16445 16438>,
			<16953 16736 16624 16481 16444 16436>,
			<17022 16809 16655 16481 16444 16435>,
			<17087 16886 16686 16482 16444 16434>,
			<17136 16950 16711 16483 16444 16433>,
			<17160 16985 16725 16483 16444 16433>,
			<17155 16984 16723 16484 16445 16433>,
			<17136 16973 16718 16484 16446 16434>,
			<17121 16962 16713 16485 16447 16435>,
			<17119 16951 16708 16488 16448 16437>,
			<17131 16942 16705 16491 16450 16439>,
			<17176 16951 16705 16495 16450 16442>,
			<17297 17030 16710 16502 16452 16445>,
			<17378 17103 16718 16510 16455 16448>,
			<17322 17111 16757 16517 16461 16451>,
			<17179 17109 16824 16525 16470 16453>,
			<17063 17101 16846 16539 16481 16457>,
			<16981 17038 16834 16572 16502 16473>,
			<16910 16939 16812 16599 16518 16487>,
			<16848 16866 16772 16591 16513 16484>,
			<16789 16808 16698 16550 16490 16467>,
			<16745 16757 16644 16515 16470 16453>,
			<16715 16713 16618 16495 16457 16445>,
			<16694 16675 16600 16481 16448 16440>,
			<16689 16639 16588 16479 16447 16440>,
			<16691 16597 16581 16480 16449 16442>,
			<16692 16563 16574 16482 16453 16445>,
			<16692 16559 16567 16486 16457 16448>,
			<16693 16574 16559 16491 16464 16451>,
			<16695 16589 16547 16497 16471 16456>,
			<16696 16597 16524 16503 16480 16465>,
			<16697 16605 16501 16508 16488 16474>,
			<16700 16614 16498 16514 16493 16477>,
			<16706 16630 16503 16519 16496 16478>,
			<16713 16647 16510 16522 16496 16477>,
			<16721 16662 16525 16512 16486 16467>,
			<16729 16677 16546 16490 16468 16454>,
			<16732 16685 16561 16475 16459 16449>,
			<16731 16682 16573 16465 16455 16448>,
			<16730 16677 16583 16460 16452 16447>,
			<16723 16671 16591 16462 16450 16445>,
			<16710 16665 16598 16468 16448 16443>,
			<16703 16660 16604 16473 16445 16440>,
			<16706 16658 16611 16476 16440 16435>,
			<16716 16660 16621 16481 16439 16432>,
			<16752 16679 16654 16503 16449 16449>,
			<16783 16709 16680 16521 16461 16467>,
			<16820 16737 16711 16540 16487 16499>,
			<16838 16756 16733 16553 16498 16499>,
			<16812 16764 16723 16539 16471 16449>,
			<16877 16712 16694 16500 16441 16437>,
			<17268 16693 16703 16511 16450 16448>,
			<18858 16840 16748 16543 16464 16461>,
			<28548 17675 16842 16597 16525 16517>,
			<28548 17675 16842 16597 16525 16517>,
			<28548 17675 16842 16597 16525 16517>;
	};

	qcom,pc-temp-y5-lut {
		qcom,lut-col-legend = <(-10) 0 10 25 40 50>;
		qcom,lut-row-legend = <10000 9800 9600 9400 9200 9000>,
			<8800 8600 8400 8200 8000 7800>,
			<7600 7400 7200 7000 6800 6600>,
			<6400 6200 6000 5800 5600 5400>,
			<5200 5000 4800 4600 4400 4200>,
			<4000 3800 3600 3400 3200 3000>,
			<2800 2600 2400 2200 2000 1800>,
			<1600 1400 1200 1000 900 800>,
			<700 600 500 400 300 200>,
			<100 0>;
		qcom,lut-data = <10272 15834 17046 19853 18912 17480>,
			<11407 15982 17241 19884 18626 18857>,
			<13101 16176 17440 19761 18344 19818>,
			<14957 16409 17631 19540 18076 20429>,
			<16578 16676 17799 19274 17833 20754>,
			<17566 16970 17930 19020 17628 20858>,
			<17839 17284 18032 18705 17462 20654>,
			<17990 17626 18121 18250 17314 20082>,
			<18070 18038 18150 17943 17191 19575>,
			<17316 18839 18004 17597 17477 19146>,
			<16170 19710 17762 17146 17968 18667>,
			<16099 19570 17582 16681 18183 18092>,
			<17531 16858 17446 15999 18455 17341>,
			<18774 14414 17246 15541 18392 16907>,
			<19971 15707 16432 15448 17538 17334>,
			<21973 19624 15167 15420 16316 18161>,
			<22365 21563 14939 15395 15706 18318>,
			<20517 21343 17364 15400 15558 17194>,
			<18404 21054 20159 15563 15654 16129>,
			<17547 21092 21088 16675 16482 16545>,
			<16955 21727 21550 19342 18373 17863>,
			<16221 22526 21959 20838 19776 18526>,
			<14732 23275 22379 20983 20683 18768>,
			<13106 24043 22772 21070 21406 19071>,
			<12562 24176 23199 21121 21440 18975>,
			<12426 20345 23712 21125 20501 18240>,
			<12379 15341 24108 21093 19364 17645>,
			<12434 13902 24339 20972 18477 17851>,
			<12533 13431 24557 20778 17681 18321>,
			<12612 13221 24671 20739 17425 18422>,
			<12810 13409 24131 20840 17440 17567>,
			<13130 13834 23083 20983 17488 16623>,
			<13365 14094 22203 21170 17787 16808>,
			<13567 14195 21018 21625 18753 17981>,
			<13695 14277 20255 22209 19386 19004>,
			<13759 14390 19998 22933 19380 19555>,
			<13820 14564 19809 23676 19338 19953>,
			<13903 14707 19442 23716 19425 20146>,
			<14036 14758 18758 21901 19975 20100>,
			<14128 14752 18235 19767 20476 20228>,
			<14020 14686 18008 18892 20351 21011>,
			<13563 14490 17695 18378 20145 22210>,
			<13153 14261 17282 18228 20394 22554>,
			<12974 14071 16610 18352 20669 21690>,
			<12950 13874 15769 18547 19838 20763>,
			<13284 13776 14718 18132 19680 22255>,
			<13537 13758 14504 17728 20007 22558>,
			<13778 13764 14415 17615 19912 20357>,
			<13992 13912 14365 17880 19000 18732>,
			<14076 13985 14377 19770 19050 21326>,
			<12605 13874 14509 21953 23403 25590>,
			<10939 13843 14410 21899 27194 28661>,
			<9786 12707 14521 22712 25874 27115>,
			<9110 10702 13997 23111 26777 26124>,
			<9110 10702 13997 23111 26777 26124>,
			<9110 10702 13997 23111 26777 26124>;
	};

	qcom,pc-temp-y6-lut {
		qcom,lut-col-legend = <(-10) 0 10 25 40 50>;
		qcom,lut-row-legend = <10000 9800 9600 9400 9200 9000>,
			<8800 8600 8400 8200 8000 7800>,
			<7600 7400 7200 7000 6800 6600>,
			<6400 6200 6000 5800 5600 5400>,
			<5200 5000 4800 4600 4400 4200>,
			<4000 3800 3600 3400 3200 3000>,
			<2800 2600 2400 2200 2000 1800>,
			<1600 1400 1200 1000 900 800>,
			<700 600 500 400 300 200>,
			<100 0>;
		qcom,lut-data = <5953 5434 5149 4982 4942 4930>,
			<5979 5453 5160 4983 4942 4931>,
			<5995 5470 5169 4984 4942 4932>,
			<6001 5484 5176 4985 4942 4932>,
			<6002 5495 5181 4985 4942 4933>,
			<5999 5500 5183 4986 4943 4934>,
			<5991 5498 5182 4986 4944 4934>,
			<5974 5491 5178 4987 4945 4935>,
			<5957 5487 5175 4987 4946 4936>,
			<5937 5488 5173 4988 4947 4937>,
			<5919 5490 5171 4990 4948 4938>,
			<5921 5490 5171 4992 4950 4939>,
			<5948 5489 5172 4993 4951 4940>,
			<5969 5487 5175 4996 4953 4941>,
			<5956 5494 5180 4999 4955 4943>,
			<5921 5512 5189 5003 4957 4945>,
			<5888 5520 5192 5008 4961 4948>,
			<5853 5497 5191 5017 4967 4952>,
			<5821 5460 5187 5024 4972 4956>,
			<5800 5436 5175 5021 4970 4954>,
			<5783 5420 5149 5006 4960 4945>,
			<5774 5408 5131 4993 4951 4939>,
			<5771 5399 5123 4986 4947 4936>,
			<5770 5393 5118 4981 4944 4934>,
			<5771 5388 5115 4981 4943 4933>,
			<5786 5380 5114 4981 4944 4934>,
			<5806 5374 5113 4982 4944 4935>,
			<5825 5376 5112 4984 4946 4936>,
			<5846 5393 5111 4986 4947 4938>,
			<5868 5417 5110 4988 4949 4940>,
			<5890 5441 5106 4990 4952 4942>,
			<5914 5470 5103 4992 4955 4944>,
			<5943 5502 5103 4994 4957 4945>,
			<5976 5539 5109 4996 4958 4946>,
			<6010 5579 5119 4997 4958 4946>,
			<6045 5625 5131 4994 4955 4943>,
			<6081 5677 5147 4988 4949 4939>,
			<6115 5732 5165 4984 4946 4937>,
			<6147 5787 5185 4981 4945 4937>,
			<6178 5844 5209 4979 4945 4937>,
			<6206 5901 5238 4980 4944 4937>,
			<6231 5960 5274 4983 4944 4936>,
			<6262 6018 5314 4987 4943 4936>,
			<6308 6071 5359 4990 4942 4934>,
			<6377 6121 5416 4995 4942 4933>,
			<6499 6191 5497 5010 4948 4941>,
			<6593 6238 5549 5020 4954 4949>,
			<6734 6295 5616 5030 4963 4958>,
			<6922 6374 5670 5036 4966 4958>,
			<7194 6463 5677 5028 4957 4942>,
			<8072 6549 5714 5013 4947 4938>,
			<10065 6791 5865 5022 4952 4943>,
			<14738 7565 6095 5039 4957 4948>,
			<28199 9555 6437 5065 4977 4967>,
			<28199 9555 6437 5065 4977 4967>,
			<28199 9555 6437 5065 4977 4967>;
	};

};
